AUTOSAR XML (schema 00046)
package /ComponentTypes
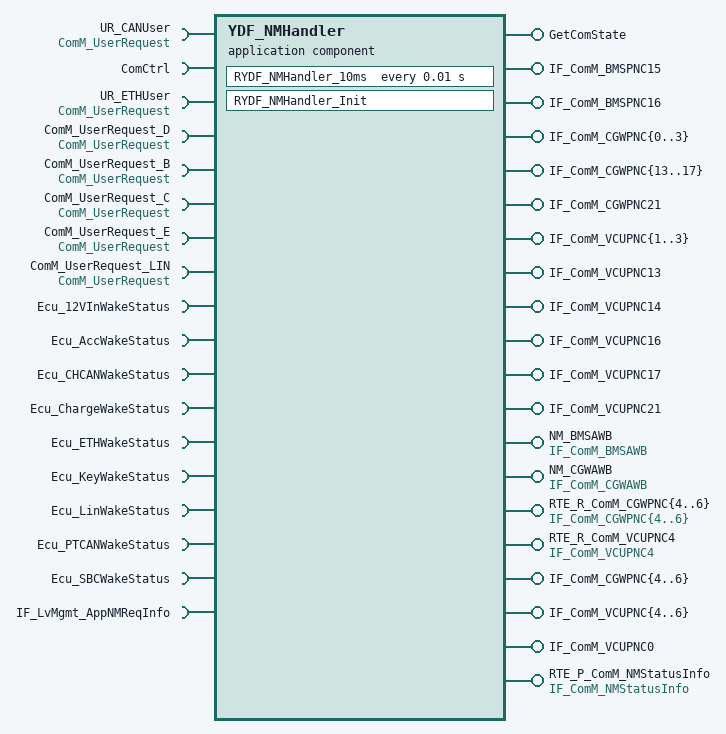
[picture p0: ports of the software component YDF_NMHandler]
  application sw component type YDF_NMHandler
    require port UR_CANUser: required-com-specs=[GetRequestedComMode, GetMaxComMode, GetCurrentComMode, RequestComMode], required-interface=ComM_UserRequest
    require port ComCtrl: nonqueued-receiver-com-spec{data-element=ComState, filter=data-filter-type=ALWAYS, init-value=constant-reference=COM_STATE_DEFAULT}, required-interface=ComCtrl
    provide port GetComState: nonqueued-sender-com-spec{data-element=State, init-value=constant-reference=COM_STATE_DEFAULT}, provided-interface=GetComState
    15 x require port:
      UR_ETHUser: required-com-specs=[RequestComMode, GetCurrentComMode, GetMaxComMode, GetRequestedComMode], required-interface=ComM_UserRequest
      ComM_UserRequest_D: required-com-specs=[GetRequestedComMode, GetMaxComMode, GetCurrentComMode, RequestComMode], required-interface=ComM_UserRequest
      ComM_UserRequest_B: required-com-specs=[GetRequestedComMode, GetMaxComMode, GetCurrentComMode, RequestComMode], required-interface=ComM_UserRequest
      ComM_UserRequest_C: required-com-specs=[GetRequestedComMode, GetMaxComMode, GetCurrentComMode, RequestComMode], required-interface=ComM_UserRequest
      ComM_UserRequest_E: required-com-specs=[GetRequestedComMode, GetMaxComMode, GetCurrentComMode, RequestComMode], required-interface=ComM_UserRequest
      ComM_UserRequest_LIN: required-com-specs=[GetRequestedComMode, GetMaxComMode, GetCurrentComMode, RequestComMode], required-interface=ComM_UserRequest
      Ecu_12VInWakeStatus: nonqueued-receiver-com-spec{data-element=st12VInwake, init-value=0}, required-interface=Ecu_12VInWakeStatus
      Ecu_AccWakeStatus: nonqueued-receiver-com-spec{data-element=Accwake, init-value=0}, required-interface=Ecu_AccWakeStatus
      Ecu_CHCANWakeStatus: nonqueued-receiver-com-spec{data-element=CHCANwake, init-value=0}, required-interface=Ecu_CHCANWakeStatus
      Ecu_ChargeWakeStatus: nonqueued-receiver-com-spec{data-element=Chargewake, init-value=0}, required-interface=Ecu_ChargeWakeStatus
      Ecu_ETHWakeStatus: nonqueued-receiver-com-spec{data-element=ETHwake, init-value=0}, required-interface=Ecu_ETHWakeStatus
      Ecu_KeyWakeStatus: nonqueued-receiver-com-spec{data-element=Keywake, init-value=0}, required-interface=Ecu_KeyWakeStatus
      Ecu_LinWakeStatus: nonqueued-receiver-com-spec{data-element=Linwake, init-value=0}, required-interface=Ecu_LinWakeStatus
      Ecu_PTCANWakeStatus: nonqueued-receiver-com-spec{data-element=PTCANwake, init-value=0}, required-interface=Ecu_PTCANWakeStatus
      Ecu_SBCWakeStatus: nonqueued-receiver-com-spec{data-element=SBCwake, init-value=0}, required-interface=Ecu_SBCWakeStatus
    22 x provide port:
      IF_ComM_BMSPNC15: nonqueued-sender-com-spec{data-element=tec_ComM_BMSPNC15, init-value=0}, provided-interface=IF_ComM_BMSPNC15
      IF_ComM_BMSPNC16: nonqueued-sender-com-spec{data-element=tec_ComM_BMSPNC16, init-value=0}, provided-interface=IF_ComM_BMSPNC16
      IF_ComM_CGWPNC{0..3}: nonqueued-sender-com-spec{data-element=tec_ComM_CGWPNC{0..3}, init-value=0}, provided-interface=IF_ComM_CGWPNC{0..3}
      IF_ComM_CGWPNC{13..17}: nonqueued-sender-com-spec{data-element=tec_ComM_CGWPNC{13..17}, init-value=0}, provided-interface=IF_ComM_CGWPNC{13..17}
      IF_ComM_CGWPNC21: nonqueued-sender-com-spec{data-element=tec_ComM_CGWPNC21, init-value=0}, provided-interface=IF_ComM_CGWPNC21
      IF_ComM_VCUPNC{1..3}: nonqueued-sender-com-spec{data-element=tec_ComM_VCUPNC{1..3}, init-value=0}, provided-interface=IF_ComM_VCUPNC{1..3}
      IF_ComM_VCUPNC13: nonqueued-sender-com-spec{data-element=tec_ComM_VCUPNC13, init-value=0}, provided-interface=IF_ComM_VCUPNC13
      IF_ComM_VCUPNC14: nonqueued-sender-com-spec{data-element=tec_ComM_VCUPNC14, init-value=0}, provided-interface=IF_ComM_VCUPNC14
      IF_ComM_VCUPNC16: nonqueued-sender-com-spec{data-element=tec_ComM_VCUPNC16, init-value=0}, provided-interface=IF_ComM_VCUPNC16
      IF_ComM_VCUPNC17: nonqueued-sender-com-spec{data-element=tec_ComM_VCUPNC17, init-value=0}, provided-interface=IF_ComM_VCUPNC17
      IF_ComM_VCUPNC21: nonqueued-sender-com-spec{data-element=tec_ComM_VCUPNC21, init-value=0}, provided-interface=IF_ComM_VCUPNC21
      NM_BMSAWB: nonqueued-sender-com-spec{data-element=tec_ComM_BMSAWB, init-value=0}, provided-interface=IF_ComM_BMSAWB
      NM_CGWAWB: nonqueued-sender-com-spec{data-element=tec_ComM_CGWAWB, init-value=0}, provided-interface=IF_ComM_CGWAWB
    require port IF_LvMgmt_AppNMReqInfo: nonqueued-receiver-com-spec{data-element=tec_LvMgmt_AppNMReqInfo, filter=data-filter-type=ALWAYS, init-value=0}, required-interface=IF_LvMgmt_AppNMReqInfo
    12 x provide port:
      RTE_R_ComM_CGWPNC{4..6}: nonqueued-sender-com-spec{data-element=tec_ComM_CGWPNC{4..6}, init-value=0}, provided-interface=IF_ComM_CGWPNC{4..6}
      RTE_R_ComM_VCUPNC4: nonqueued-sender-com-spec{data-element=tec_ComM_VCUPNC4, init-value=0}, provided-interface=IF_ComM_VCUPNC4
      IF_ComM_CGWPNC{4..6}: nonqueued-sender-com-spec{data-element=tec_ComM_CGWPNC{4..6}, init-value=0}, provided-interface=IF_ComM_CGWPNC{4..6}
      IF_ComM_VCUPNC{4..6}: nonqueued-sender-com-spec{data-element=tec_ComM_VCUPNC{4..6}, init-value=0}, provided-interface=IF_ComM_VCUPNC{4..6}
      IF_ComM_VCUPNC0: nonqueued-sender-com-spec{data-element=tec_ComM_VCUPNC0, init-value=0}, provided-interface=IF_ComM_VCUPNC0
      RTE_P_ComM_NMStatusInfo: nonqueued-sender-com-spec{data-element=tec_ComM_NMStatusInfo, init-value=0}, provided-interface=IF_ComM_NMStatusInfo
    behavior YDF_NMHandler_InternalBehavior
      init event RYDS_NMHandler_InitEvent: start-on-event=RYDF_NMHandler_Init
      timing event TMT_RYDS_NMHandler_10ms: start-on-event=RYDF_NMHandler_10ms, period=0.01
      runnable RYDF_NMHandler_Init
      runnable RYDF_NMHandler_10ms
        data-receive-point-by-arguments:
          11 x access:
            REC_ComCtrl_ComState: accessed-variable=ComCtrl.ComState
            REC_Ecu_12VInWakeStatus_st12VInwake: accessed-variable=Ecu_12VInWakeStatus.st12VInwake
            REC_Ecu_AccWakeStatus_Accwake: accessed-variable=Ecu_AccWakeStatus.Accwake
            REC_Ecu_CHCANWakeStatus_CHCANwake: accessed-variable=Ecu_CHCANWakeStatus.CHCANwake
            REC_Ecu_ChargeWakeStatus_Chargewake: accessed-variable=Ecu_ChargeWakeStatus.Chargewake
            REC_Ecu_ETHWakeStatus_ETHwake: accessed-variable=Ecu_ETHWakeStatus.ETHwake
            REC_Ecu_KeyWakeStatus_Keywake: accessed-variable=Ecu_KeyWakeStatus.Keywake
            REC_Ecu_LinWakeStatus_Linwake: accessed-variable=Ecu_LinWakeStatus.Linwake
            REC_Ecu_PTCANWakeStatus_PTCANwake: accessed-variable=Ecu_PTCANWakeStatus.PTCANwake
            REC_Ecu_SBCWakeStatus_SBCwake: accessed-variable=Ecu_SBCWakeStatus.SBCwake
            REC_IF_LvMgmt_AppNMReqInfo_tec_LvMgmt_AppNMReqInfo: accessed-variable=IF_LvMgmt_AppNMReqInfo.tec_LvMgmt_AppNMReqInfo
        data-send-points:
          35 x access:
            SEND_GetComState_State: accessed-variable=GetComState.State
            SEND_IF_ComM_BMSPNC15_tec_ComM_BMSPNC15: accessed-variable=IF_ComM_BMSPNC15.tec_ComM_BMSPNC15
            SEND_IF_ComM_BMSPNC16_tec_ComM_BMSPNC16: accessed-variable=IF_ComM_BMSPNC16.tec_ComM_BMSPNC16
            SEND_IF_ComM_CGWPNC0_tec_ComM_CGWPNC0: accessed-variable=IF_ComM_CGWPNC0.tec_ComM_CGWPNC0
            SEND_IF_ComM_CGWPNC1_tec_ComM_CGWPNC1: accessed-variable=IF_ComM_CGWPNC1.tec_ComM_CGWPNC1
            SEND_IF_ComM_CGWPNC{13..17}_tec_ComM_CGWPNC{13..17}: accessed-variable=IF_ComM_CGWPNC{13..17}.tec_ComM_CGWPNC{13..17}
            SEND_IF_ComM_CGWPNC2_tec_ComM_CGWPNC2: accessed-variable=IF_ComM_CGWPNC2.tec_ComM_CGWPNC2
            SEND_IF_ComM_CGWPNC21_tec_ComM_CGWPNC21: accessed-variable=IF_ComM_CGWPNC21.tec_ComM_CGWPNC21
            SEND_IF_ComM_CGWPNC3_tec_ComM_CGWPNC3: accessed-variable=IF_ComM_CGWPNC3.tec_ComM_CGWPNC3
            SEND_IF_ComM_VCUPNC1_tec_ComM_VCUPNC1: accessed-variable=IF_ComM_VCUPNC1.tec_ComM_VCUPNC1
            SEND_IF_ComM_VCUPNC13_tec_ComM_VCUPNC13: accessed-variable=IF_ComM_VCUPNC13.tec_ComM_VCUPNC13
            SEND_IF_ComM_VCUPNC14_tec_ComM_VCUPNC14: accessed-variable=IF_ComM_VCUPNC14.tec_ComM_VCUPNC14
            SEND_IF_ComM_VCUPNC16_tec_ComM_VCUPNC16: accessed-variable=IF_ComM_VCUPNC16.tec_ComM_VCUPNC16
            SEND_IF_ComM_VCUPNC17_tec_ComM_VCUPNC17: accessed-variable=IF_ComM_VCUPNC17.tec_ComM_VCUPNC17
            SEND_IF_ComM_VCUPNC2_tec_ComM_VCUPNC2: accessed-variable=IF_ComM_VCUPNC2.tec_ComM_VCUPNC2
            SEND_IF_ComM_VCUPNC21_tec_ComM_VCUPNC21: accessed-variable=IF_ComM_VCUPNC21.tec_ComM_VCUPNC21
            SEND_IF_ComM_VCUPNC3_tec_ComM_VCUPNC3: accessed-variable=IF_ComM_VCUPNC3.tec_ComM_VCUPNC3
            SEND_NM_CGWAWB_tec_ComM_CGWAWB: accessed-variable=NM_CGWAWB.tec_ComM_CGWAWB
            SEND_NM_BMSAWB_tec_ComM_BMSAWB: accessed-variable=NM_BMSAWB.tec_ComM_BMSAWB
            SEND_IF_ComM_CGWPNC{4..6}_tec_ComM_CGWPNC{4..6}: accessed-variable=IF_ComM_CGWPNC{4..6}.tec_ComM_CGWPNC{4..6}
            SEND_IF_ComM_VCUPNC0_tec_ComM_VCUPNC0: accessed-variable=IF_ComM_VCUPNC0.tec_ComM_VCUPNC0
            SEND_IF_ComM_VCUPNC{4..6}_tec_ComM_VCUPNC{4..6}: accessed-variable=IF_ComM_VCUPNC{4..6}.tec_ComM_VCUPNC{4..6}
            SEND_RTE_P_ComM_NMStatusInfo_tec_ComM_NMStatusInfo: accessed-variable=RTE_P_ComM_NMStatusInfo.tec_ComM_NMStatusInfo
            SEND_RTE_R_ComM_CGWPNC{4..6}_tec_ComM_CGWPNC{4..6}: accessed-variable=RTE_R_ComM_CGWPNC{4..6}.tec_ComM_CGWPNC{4..6}
            SEND_RTE_R_ComM_VCUPNC4_tec_ComM_VCUPNC4: accessed-variable=RTE_R_ComM_VCUPNC4.tec_ComM_VCUPNC4
        28 x sync call:
          SC_ComM_UserRequest_GetCurrentComMode: operation=UR_CANUser.GetCurrentComMode
          SC_ComM_UserRequest_GetMaxComMode: operation=UR_CANUser.GetMaxComMode
          SC_ComM_UserRequest_GetRequestedComMode: operation=UR_CANUser.GetRequestedComMode
          SC_ComM_UserRequest_RequestComMode: operation=UR_CANUser.RequestComMode
          SC_UR_ETHUser_RequestComMode: operation=UR_ETHUser.RequestComMode
          SC_ComM_UserRequest_D_GetCurrentComMode: operation=ComM_UserRequest_D.GetCurrentComMode
          SC_ComM_UserRequest_D_GetMaxComMode: operation=ComM_UserRequest_D.GetMaxComMode
          SC_ComM_UserRequest_D_GetRequestedComMode: operation=ComM_UserRequest_D.GetRequestedComMode
          SC_ComM_UserRequest_D_RequestComMode: operation=ComM_UserRequest_D.RequestComMode
          SC_ComM_UserRequest_B_GetCurrentComMode: operation=ComM_UserRequest_B.GetCurrentComMode
          SC_ComM_UserRequest_B_GetMaxComMode: operation=ComM_UserRequest_B.GetMaxComMode
          SC_ComM_UserRequest_B_GetRequestedComMode: operation=ComM_UserRequest_B.GetRequestedComMode
          SC_ComM_UserRequest_B_RequestComMode: operation=ComM_UserRequest_B.RequestComMode
          SC_ComM_UserRequest_C_GetCurrentComMode: operation=ComM_UserRequest_C.GetCurrentComMode
          SC_ComM_UserRequest_C_GetMaxComMode: operation=ComM_UserRequest_C.GetMaxComMode
          SC_ComM_UserRequest_C_GetRequestedComMode: operation=ComM_UserRequest_C.GetRequestedComMode
          SC_ComM_UserRequest_C_RequestComMode: operation=ComM_UserRequest_C.RequestComMode
          SC_ComM_UserRequest_E_GetCurrentComMode: operation=ComM_UserRequest_E.GetCurrentComMode
          SC_ComM_UserRequest_E_GetMaxComMode: operation=ComM_UserRequest_E.GetMaxComMode
          SC_ComM_UserRequest_E_GetRequestedComMode: operation=ComM_UserRequest_E.GetRequestedComMode
          SC_ComM_UserRequest_E_RequestComMode: operation=ComM_UserRequest_E.RequestComMode
          SC_ComM_UserRequest_LIN_GetCurrentComMode: operation=ComM_UserRequest_LIN.GetCurrentComMode
          SC_ComM_UserRequest_LIN_GetMaxComMode: operation=ComM_UserRequest_LIN.GetMaxComMode
          SC_ComM_UserRequest_LIN_GetRequestedComMode: operation=ComM_UserRequest_LIN.GetRequestedComMode
          SC_ComM_UserRequest_LIN_RequestComMode: operation=ComM_UserRequest_LIN.RequestComMode
          SC_UR_ETHUser_GetCurrentComMode: operation=UR_ETHUser.GetCurrentComMode
          SC_UR_ETHUser_GetMaxComMode: operation=UR_ETHUser.GetMaxComMode
          SC_UR_ETHUser_GetRequestedComMode: operation=UR_ETHUser.GetRequestedComMode
  swc implementation YDF_NMHandler_Implementation: behavior=YDF_NMHandler_InternalBehavior
    code-descriptors:
      code Default: artifact-descriptors=autosar-engineering-object=category=SWSRC
